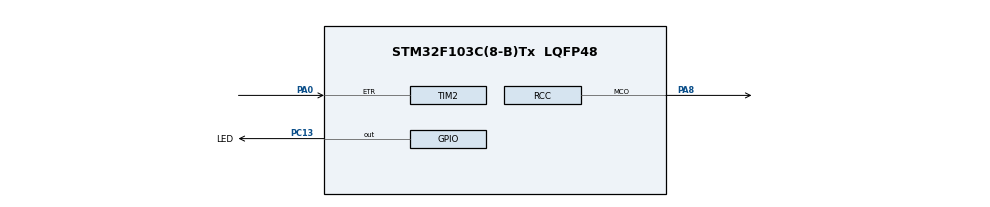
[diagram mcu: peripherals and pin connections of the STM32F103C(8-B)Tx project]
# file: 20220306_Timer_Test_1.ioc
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Mcu.Family=STM32F1
Mcu.Name=STM32F103C(8-B)Tx
Mcu.Package=LQFP48
NVIC.PriorityGroup=NVIC_PRIORITYGROUP_4
PA0-WKUP.Signal=S_TIM2_CH1_ETR
PA13.Mode=Serial_Wire
PA13.Signal=SYS_JTMS-SWDIO
PA14.Mode=Serial_Wire
PA14.Signal=SYS_JTCK-SWCLK
PA8.Mode=Clock-out
PA8.Signal=RCC_MCO
PC13-TAMPER-RTC.GPIO_Label=LED
PC13-TAMPER-RTC.Signal=GPIO_Output
PC14-OSC32_IN.Mode=LSE-External-Oscillator
PC14-OSC32_IN.Signal=RCC_OSC32_IN
PC15-OSC32_OUT.Mode=LSE-External-Oscillator
PC15-OSC32_OUT.Signal=RCC_OSC32_OUT
PD0-OSC_IN.Mode=HSE-External-Oscillator
PD0-OSC_IN.Signal=RCC_OSC_IN
PD1-OSC_OUT.Mode=HSE-External-Oscillator
PD1-OSC_OUT.Signal=RCC_OSC_OUT
ProjectManager.HeapSize=0x200
ProjectManager.StackSize=0x400
ProjectManager.TargetToolchain=STM32CubeIDE
RCC.APB1Freq_Value=8000000
RCC.APB2Freq_Value=8000000
RCC.RCC_MCOSource=RCC_MCO1SOURCE_PLLCLK
RCC.SYSCLKSource=RCC_SYSCLKSOURCE_HSE
SH.S_TIM2_CH1_ETR.0=TIM2_ETR,ClockSourceETR_Mode2
TIM2.AutoReloadPreload=TIM_AUTORELOAD_PRELOAD_ENABLE
TIM2.Period=20
TIM2.Prescaler=65535
board=custom

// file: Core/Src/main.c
/* USER CODE BEGIN Header */
/**
  ******************************************************************************
  * @file           : main.c
  * @brief          : Main program body
  ******************************************************************************
  * @attention
  *
  * Copyright (c) 2022 STMicroelectronics.
  * All rights reserved.
  *
  * This software is licensed under terms that can be found in the LICENSE file
  * in the root directory of this software component.
  * If no LICENSE file comes with this software, it is provided AS-IS.
  *
  ******************************************************************************
  */
/* USER CODE END Header */
#include "main.h"
#include "tim.h"
#include "gpio.h"

void SystemClock_Config(void);

int main(void)
{

  /* MCU Configuration--------------------------------------------------------*/

  /* Reset of all peripherals, Initializes the Flash interface and the Systick. */
  HAL_Init();

  /* Configure the system clock */
  SystemClock_Config();

  /* Initialize all configured peripherals */
  MX_GPIO_Init();
  MX_TIM2_Init();
  /* USER CODE BEGIN 2 */
  HAL_TIM_Base_Start_IT(&htim2);
  /* USER CODE END 2 */

  /* Infinite loop */
  while (1)
  {

    /* USER CODE BEGIN 3 */

    if((TIM2->CNT) > htim2.Init.Period/2)
    {
      /*LED is on*/
      HAL_GPIO_WritePin(LED_GPIO_Port, LED_Pin, GPIO_PIN_RESET);
    }
    else
    {
      /*LED is off*/
      HAL_GPIO_WritePin(LED_GPIO_Port, LED_Pin, GPIO_PIN_SET);
    }

  }
  /* USER CODE END 3 */
}

void SystemClock_Config(void)
{
  RCC_OscInitTypeDef RCC_OscInitStruct = {0};
  RCC_ClkInitTypeDef RCC_ClkInitStruct = {0};

  /** Initializes the RCC Oscillators according to the specified parameters
  * in the RCC_OscInitTypeDef structure.
  */
  RCC_OscInitStruct.OscillatorType = RCC_OSCILLATORTYPE_HSI|RCC_OSCILLATORTYPE_HSE;
  RCC_OscInitStruct.HSEState = RCC_HSE_ON;
  RCC_OscInitStruct.HSIState = RCC_HSI_ON;
  RCC_OscInitStruct.HSICalibrationValue = RCC_HSICALIBRATION_DEFAULT;
  RCC_OscInitStruct.PLL.PLLState = RCC_PLL_ON;
  RCC_OscInitStruct.PLL.PLLSource = RCC_PLLSOURCE_HSI_DIV2;
  RCC_OscInitStruct.PLL.PLLMUL = RCC_PLL_MUL2;
  if (HAL_RCC_OscConfig(&RCC_OscInitStruct) != HAL_OK)
  {
    Error_Handler();
  }
  /** Initializes the CPU, AHB and APB buses clocks
  */
  RCC_ClkInitStruct.ClockType = RCC_CLOCKTYPE_HCLK|RCC_CLOCKTYPE_SYSCLK
                              |RCC_CLOCKTYPE_PCLK1|RCC_CLOCKTYPE_PCLK2;
  RCC_ClkInitStruct.SYSCLKSource = RCC_SYSCLKSOURCE_HSE;
  RCC_ClkInitStruct.AHBCLKDivider = RCC_SYSCLK_DIV1;
  RCC_ClkInitStruct.APB1CLKDivider = RCC_HCLK_DIV1;
  RCC_ClkInitStruct.APB2CLKDivider = RCC_HCLK_DIV1;

  if (HAL_RCC_ClockConfig(&RCC_ClkInitStruct, FLASH_LATENCY_0) != HAL_OK)
  {
    Error_Handler();
  }
  HAL_RCC_MCOConfig(RCC_MCO, RCC_MCO1SOURCE_PLLCLK, RCC_MCODIV_1);
}

void Error_Handler(void)
{
  __disable_irq();
  while (1)
  {
  }
}
